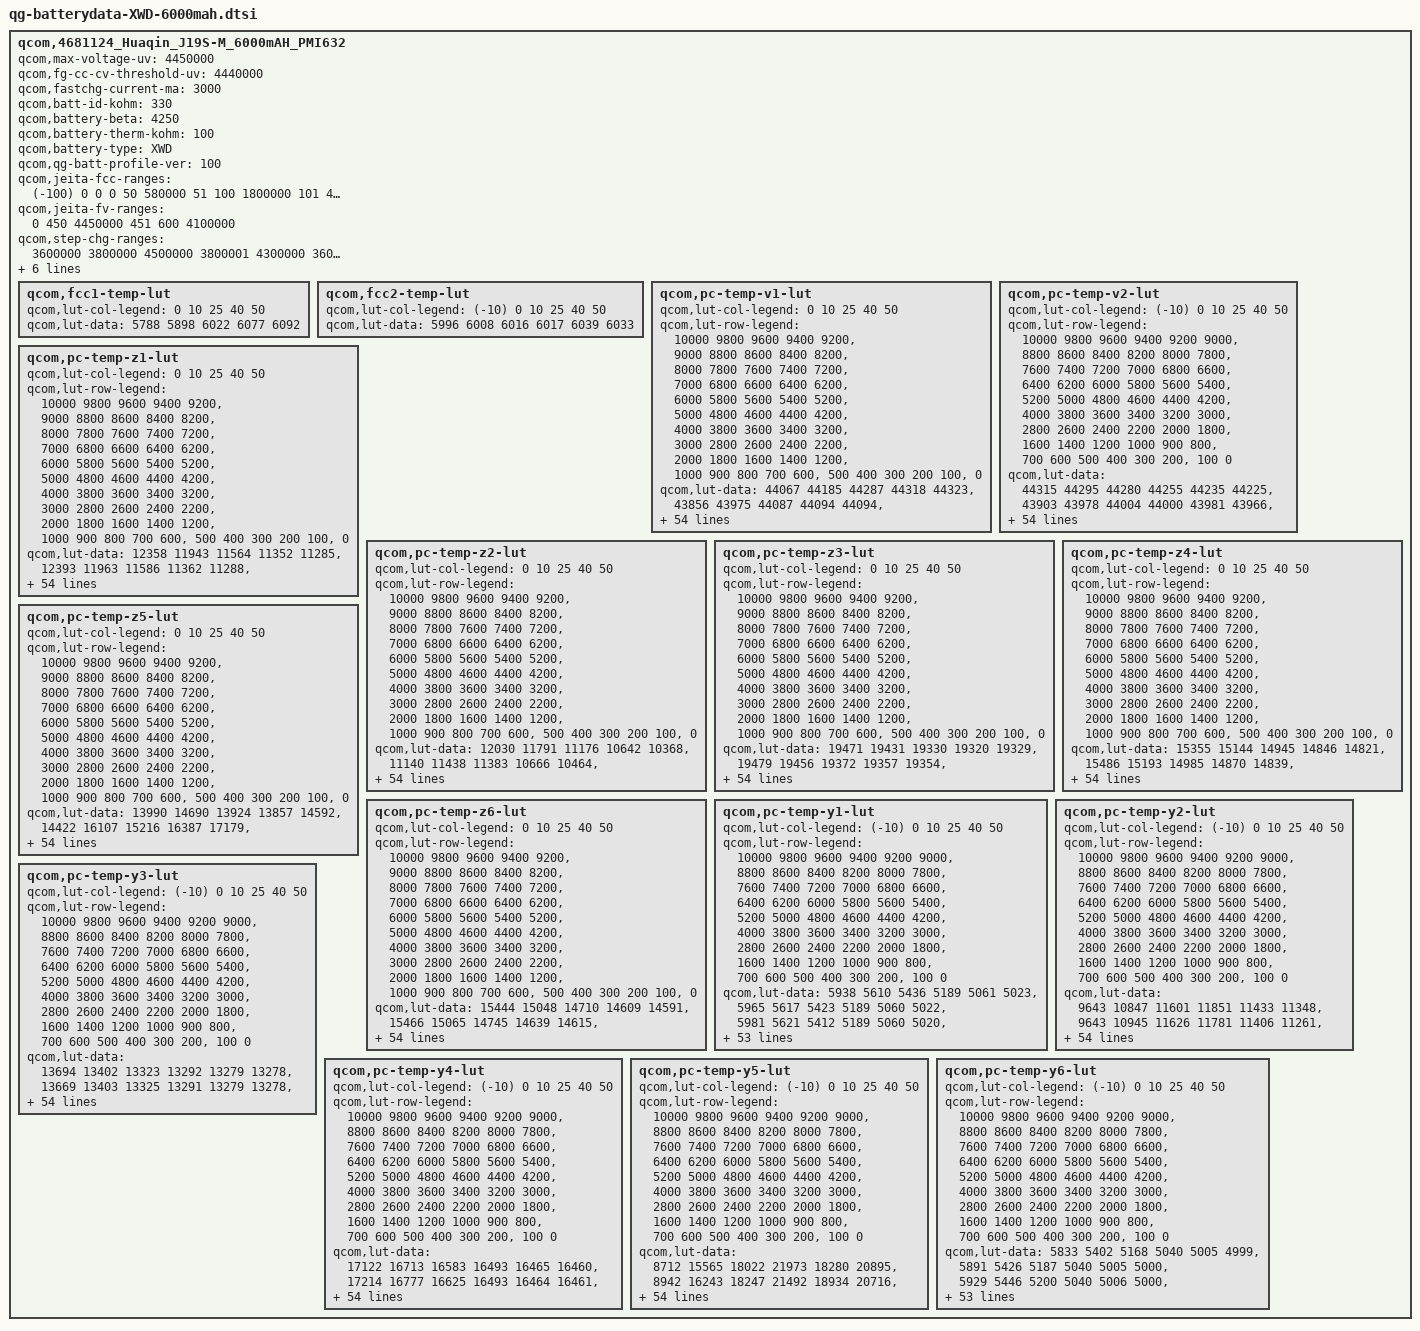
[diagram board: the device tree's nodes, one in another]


qcom,4681124_Huaqin_J19S-M_6000mAH_PMI632 {
    /* 4681124_Huaqin_J19S-M_6000mAH_PMI632_averaged_MasterSlave_Aug12th2020 */
    qcom,max-voltage-uv = <4450000>;
    qcom,fg-cc-cv-threshold-uv = <4440000>;
    qcom,fastchg-current-ma = <3000>;
    qcom,batt-id-kohm = <330>;
    qcom,battery-beta = <4250>;
    qcom,battery-therm-kohm = <100>;
    qcom,battery-type = "XWD";
    qcom,qg-batt-profile-ver = <100>;

	qcom,jeita-fcc-ranges = <(-100) 0 0
				0  50    580000
				51  100  1800000
				101 450  3000000
				451 600  3000000>;
	qcom,jeita-fv-ranges = <0   450   4450000
				451 600  4100000>;
	qcom,step-chg-ranges = <3600000  3800000  4500000
				3800001  4300000  3600000
				4300001  4350000  2500000>;
	qcom,ocv-based-step-chg;

	/* COOL = 5 DegC, WARM = 45 DegC */
	qcom,jeita-soft-thresholds = <0x439d 0x20b8>;
	/* COLD = 0 DegC, HOT = 60 DegC */
	qcom,jeita-hard-thresholds = <0x58cd 0x14f3>;
	/* COOL hys = 12 DegC, WARM hys = 40 DegC */
	qcom,jeita-soft-hys-thresholds = <0x4777 0x25e3>;
	qcom,jeita-soft-fcc-ua = <2500000 2500000>;
	qcom,jeita-soft-fv-uv = <4250000 4250000>;

	qcom,fcc1-temp-lut {
		qcom,lut-col-legend = <0 10 25 40 50>;
		qcom,lut-data = <5788 5898 6022 6077 6092>;
	};

	qcom,fcc2-temp-lut {
		qcom,lut-col-legend = <(-10) 0 10 25 40 50>;
		qcom,lut-data = <5996 6008 6016 6017 6039 6033>;
	};

	qcom,pc-temp-v1-lut {
		qcom,lut-col-legend = <0 10 25 40 50>;
		qcom,lut-row-legend = <10000 9800 9600 9400 9200>,
			<9000 8800 8600 8400 8200>,
			<8000 7800 7600 7400 7200>,
			<7000 6800 6600 6400 6200>,
			<6000 5800 5600 5400 5200>,
			<5000 4800 4600 4400 4200>,
			<4000 3800 3600 3400 3200>,
			<3000 2800 2600 2400 2200>,
			<2000 1800 1600 1400 1200>,
			<1000 900 800 700 600>,
			<500 400 300 200 100>,
			<0>;
		qcom,lut-data = <44067 44185 44287 44318 44323>,
			<43856 43975 44087 44094 44094>,
			<43631 43760 43881 43888 43886>,
			<43399 43542 43671 43683 43682>,
			<43164 43318 43454 43467 43469>,
			<42922 43083 43228 43245 43251>,
			<42680 42840 42989 43015 43024>,
			<42438 42598 42740 42775 42786>,
			<42198 42354 42493 42531 42542>,
			<41963 42112 42249 42289 42299>,
			<41735 41876 42008 42046 42055>,
			<41513 41643 41770 41806 41815>,
			<41294 41418 41536 41568 41578>,
			<41081 41201 41308 41336 41345>,
			<40872 40989 41086 41111 41119>,
			<40669 40780 40871 40893 40900>,
			<40472 40575 40663 40683 40689>,
			<40282 40381 40462 40479 40485>,
			<40098 40211 40273 40285 40291>,
			<39922 40046 40101 40110 40118>,
			<39761 39857 39919 39935 39946>,
			<39600 39636 39683 39713 39727>,
			<39403 39411 39419 39441 39447>,
			<39150 39178 39206 39214 39214>,
			<38934 38957 39032 39048 39056>,
			<38800 38822 38888 38910 38926>,
			<38698 38741 38777 38792 38801>,
			<38624 38672 38685 38690 38684>,
			<38571 38599 38597 38594 38578>,
			<38526 38528 38512 38496 38482>,
			<38478 38462 38434 38405 38396>,
			<38430 38398 38361 38324 38318>,
			<38385 38340 38292 38251 38246>,
			<38341 38289 38229 38183 38175>,
			<38299 38245 38174 38121 38105>,
			<38262 38203 38123 38061 38035>,
			<38230 38168 38076 38003 37967>,
			<38189 38129 38032 37945 37901>,
			<38122 38066 37968 37871 37818>,
			<38028 37973 37874 37768 37707>,
			<37920 37864 37764 37651 37584>,
			<37785 37730 37644 37532 37459>,
			<37630 37578 37505 37402 37325>,
			<37443 37402 37335 37235 37154>,
			<37332 37248 37187 37101 37030>,
			<37235 37152 37092 37023 36967>,
			<37200 37123 37067 36999 36938>,
			<37166 37103 37051 36979 36920>,
			<37134 37078 37026 36956 36892>,
			<37057 37015 36955 36855 36778>,
			<36766 36742 36657 36510 36418>,
			<36277 36276 36191 36032 35940>,
			<35652 35672 35587 35415 35321>,
			<34795 34843 34762 34565 34470>,
			<33394 33530 33479 33219 33117>,
			<30000 30000 30000 30000 30000>;
	};

	qcom,pc-temp-v2-lut {
		qcom,lut-col-legend = <(-10) 0 10 25 40 50>;
		qcom,lut-row-legend = <10000 9800 9600 9400 9200 9000>,
			<8800 8600 8400 8200 8000 7800>,
			<7600 7400 7200 7000 6800 6600>,
			<6400 6200 6000 5800 5600 5400>,
			<5200 5000 4800 4600 4400 4200>,
			<4000 3800 3600 3400 3200 3000>,
			<2800 2600 2400 2200 2000 1800>,
			<1600 1400 1200 1000 900 800>,
			<700 600 500 400 300 200>,
			<100 0>;
		qcom,lut-data = <44315 44295 44280 44255 44235 44225>,
			<43903 43978 44004 44000 43981 43966>,
			<43546 43688 43744 43755 43737 43719>,
			<43260 43428 43504 43522 43506 43487>,
			<43033 43200 43285 43302 43288 43270>,
			<42803 42970 43061 43078 43066 43049>,
			<42542 42723 42819 42840 42829 42814>,
			<42266 42470 42569 42596 42587 42573>,
			<41964 42217 42322 42352 42344 42331>,
			<41610 41964 42076 42108 42100 42087>,
			<41359 41706 41833 41867 41858 41846>,
			<41262 41418 41594 41628 41619 41608>,
			<41189 41141 41359 41392 41385 41375>,
			<41022 40954 41132 41164 41155 41145>,
			<40657 40832 40911 40943 40930 40921>,
			<40293 40687 40698 40728 40713 40704>,
			<40031 40454 40491 40520 40505 40495>,
			<39794 40175 40288 40318 40305 40293>,
			<39554 39926 40090 40126 40117 40107>,
			<39315 39693 39896 39947 39940 39932>,
			<39079 39460 39686 39749 39745 39741>,
			<38819 39212 39429 39499 39502 39503>,
			<38577 38970 39165 39238 39253 39257>,
			<38434 38762 38955 39026 39044 39050>,
			<38341 38579 38778 38846 38859 38865>,
			<38268 38418 38623 38693 38704 38709>,
			<38206 38267 38488 38566 38577 38581>,
			<38151 38138 38368 38455 38466 38469>,
			<38097 38062 38255 38353 38365 38365>,
			<38046 38011 38149 38258 38272 38269>,
			<37994 37966 38056 38170 38187 38181>,
			<37941 37923 37971 38086 38111 38105>,
			<37887 37881 37900 38008 38037 38031>,
			<37829 37837 37851 37936 37962 37952>,
			<37767 37792 37818 37869 37888 37869>,
			<37702 37743 37781 37801 37803 37776>,
			<37636 37686 37739 37730 37703 37667>,
			<37565 37622 37690 37656 37599 37554>,
			<37488 37546 37624 37577 37507 37457>,
			<37404 37457 37537 37494 37420 37368>,
			<37312 37353 37434 37402 37325 37272>,
			<37199 37220 37303 37296 37219 37167>,
			<37082 37084 37157 37174 37098 37047>,
			<36981 36970 37004 37024 36955 36901>,
			<36892 36857 36886 36916 36866 36815>,
			<36812 36745 36798 36868 36833 36785>,
			<36772 36681 36756 36853 36822 36774>,
			<36731 36618 36712 36834 36805 36755>,
			<36676 36554 36653 36797 36760 36704>,
			<36570 36443 36529 36685 36565 36497>,
			<36358 36236 36262 36351 36145 36065>,
			<35936 35810 35792 35826 35584 35503>,
			<35294 35163 35120 35153 34844 34762>,
			<34387 34232 34220 34224 33804 33735>,
			<32941 32628 32790 32646 32013 32000>,
			<29059 27445 28705 28453 27208 27221>;
	};

	qcom,pc-temp-z1-lut {
		qcom,lut-col-legend = <0 10 25 40 50>;
		qcom,lut-row-legend = <10000 9800 9600 9400 9200>,
			<9000 8800 8600 8400 8200>,
			<8000 7800 7600 7400 7200>,
			<7000 6800 6600 6400 6200>,
			<6000 5800 5600 5400 5200>,
			<5000 4800 4600 4400 4200>,
			<4000 3800 3600 3400 3200>,
			<3000 2800 2600 2400 2200>,
			<2000 1800 1600 1400 1200>,
			<1000 900 800 700 600>,
			<500 400 300 200 100>,
			<0>;
		qcom,lut-data = <12358 11943 11564 11352 11285>,
			<12393 11963 11586 11362 11288>,
			<12406 11972 11590 11366 11298>,
			<12414 11975 11590 11369 11305>,
			<12409 11976 11581 11367 11306>,
			<12389 11975 11571 11361 11306>,
			<12372 11971 11566 11357 11305>,
			<12366 11965 11560 11356 11303>,
			<12362 11951 11555 11354 11302>,
			<12358 11937 11548 11353 11304>,
			<12354 11929 11543 11352 11308>,
			<12349 11921 11542 11352 11310>,
			<12345 11914 11541 11353 11311>,
			<12340 11909 11540 11353 11312>,
			<12334 11906 11540 11353 11313>,
			<12323 11905 11540 11353 11314>,
			<12311 11907 11541 11353 11315>,
			<12304 11907 11541 11354 11316>,
			<12300 11906 11542 11355 11316>,
			<12298 11906 11546 11357 11318>,
			<12299 11907 11549 11360 11321>,
			<12301 11909 11548 11361 11323>,
			<12301 11911 11548 11361 11324>,
			<12296 11911 11548 11362 11326>,
			<12294 11910 11552 11364 11328>,
			<12301 11912 11557 11367 11330>,
			<12314 11918 11561 11370 11332>,
			<12319 11923 11565 11373 11334>,
			<12317 11924 11568 11376 11337>,
			<12313 11924 11571 11379 11340>,
			<12314 11926 11575 11383 11344>,
			<12317 11932 11578 11386 11348>,
			<12317 11938 11582 11390 11351>,
			<12313 11938 11585 11394 11355>,
			<12308 11936 11590 11398 11359>,
			<12311 11936 11594 11403 11364>,
			<12331 11939 11598 11407 11368>,
			<12348 11944 11601 11411 11371>,
			<12354 11950 11606 11415 11374>,
			<12358 11958 11614 11419 11378>,
			<12366 11966 11621 11423 11381>,
			<12387 11973 11625 11427 11384>,
			<12395 11981 11628 11431 11388>,
			<12391 11994 11637 11434 11389>,
			<12405 11992 11651 11439 11393>,
			<12392 12003 11649 11447 11396>,
			<12420 11997 11651 11445 11395>,
			<12544 12003 11652 11446 11397>,
			<12388 12002 11657 11448 11400>,
			<12421 11996 11661 11452 11404>,
			<12433 12016 11675 11461 11407>,
			<12422 12006 11681 11465 11411>,
			<12414 12024 11692 11473 11421>,
			<12428 12040 11698 11483 11432>,
			<12428 12040 11698 11483 11432>,
			<12428 12040 11698 11483 11432>;
	};

	qcom,pc-temp-z2-lut {
		qcom,lut-col-legend = <0 10 25 40 50>;
		qcom,lut-row-legend = <10000 9800 9600 9400 9200>,
			<9000 8800 8600 8400 8200>,
			<8000 7800 7600 7400 7200>,
			<7000 6800 6600 6400 6200>,
			<6000 5800 5600 5400 5200>,
			<5000 4800 4600 4400 4200>,
			<4000 3800 3600 3400 3200>,
			<3000 2800 2600 2400 2200>,
			<2000 1800 1600 1400 1200>,
			<1000 900 800 700 600>,
			<500 400 300 200 100>,
			<0>;
		qcom,lut-data = <12030 11791 11176 10642 10368>,
			<11140 11438 11383 10666 10464>,
			<11086 11259 11841 10733 10549>,
			<11057 11203 12015 10755 10614>,
			<11013 11154 11842 10749 10613>,
			<10961 11102 11570 10731 10561>,
			<10919 11046 11287 10708 10542>,
			<10888 11001 10965 10670 10533>,
			<10862 10963 10814 10629 10523>,
			<10847 10932 10767 10584 10519>,
			<10835 10914 10742 10543 10513>,
			<10829 10900 10739 10537 10512>,
			<10833 10895 10749 10551 10516>,
			<10840 10904 10755 10567 10520>,
			<10846 10921 10755 10583 10530>,
			<10854 10942 10757 10599 10545>,
			<10867 10970 10780 10606 10549>,
			<10887 11000 10826 10603 10557>,
			<10916 11110 10861 10604 10554>,
			<10943 11282 10884 10627 10500>,
			<10970 11313 10911 10670 10432>,
			<10990 11177 10980 10764 10488>,
			<10992 11055 11076 10965 10815>,
			<10983 11039 11093 11058 11004>,
			<10976 11031 11008 10882 10838>,
			<10982 11032 10937 10669 10616>,
			<10997 11054 10957 10675 10702>,
			<11010 11080 11007 10775 11138>,
			<11020 11099 11032 10858 11346>,
			<11030 11116 11047 10917 11148>,
			<11044 11124 11052 10954 10864>,
			<11063 11132 11048 10920 10704>,
			<11081 11139 11041 10814 10584>,
			<11094 11141 11031 10746 10499>,
			<11107 11140 11010 10708 10431>,
			<11120 11143 10997 10687 10391>,
			<11133 11156 11011 10705 10420>,
			<11151 11176 11048 10762 10517>,
			<11185 11199 11096 10838 10617>,
			<11234 11231 11180 10972 10732>,
			<11274 11264 11238 11066 10823>,
			<11303 11292 11246 11051 10863>,
			<11361 11330 11253 11025 10888>,
			<11510 11389 11268 11044 10939>,
			<10869 11756 11368 11024 10920>,
			<10531 11936 11441 10943 10669>,
			<10567 11913 11414 10817 10691>,
			<10489 11962 11374 10815 10686>,
			<10896 12014 11397 10965 10738>,
			<10801 12087 11502 10960 10772>,
			<10529 12204 11553 10832 10590>,
			<10510 12209 11303 10605 10408>,
			<10064 11914 11275 10484 10330>,
			<9893 11427 11180 10434 10282>,
			<9893 11427 11180 10434 10282>,
			<9893 11427 11180 10434 10282>;
	};

	qcom,pc-temp-z3-lut {
		qcom,lut-col-legend = <0 10 25 40 50>;
		qcom,lut-row-legend = <10000 9800 9600 9400 9200>,
			<9000 8800 8600 8400 8200>,
			<8000 7800 7600 7400 7200>,
			<7000 6800 6600 6400 6200>,
			<6000 5800 5600 5400 5200>,
			<5000 4800 4600 4400 4200>,
			<4000 3800 3600 3400 3200>,
			<3000 2800 2600 2400 2200>,
			<2000 1800 1600 1400 1200>,
			<1000 900 800 700 600>,
			<500 400 300 200 100>,
			<0>;
		qcom,lut-data = <19471 19431 19330 19320 19329>,
			<19479 19456 19372 19357 19354>,
			<19532 19471 19391 19370 19368>,
			<19582 19489 19403 19384 19378>,
			<19600 19507 19422 19394 19385>,
			<19611 19517 19438 19403 19390>,
			<19618 19523 19442 19408 19394>,
			<19627 19525 19443 19410 19397>,
			<19633 19525 19444 19411 19400>,
			<19634 19524 19443 19411 19401>,
			<19626 19523 19440 19409 19402>,
			<19619 19520 19437 19408 19401>,
			<19616 19515 19432 19405 19398>,
			<19615 19507 19426 19402 19393>,
			<19616 19499 19417 19398 19389>,
			<19618 19496 19410 19392 19385>,
			<19619 19495 19408 19388 19380>,
			<19615 19494 19406 19384 19376>,
			<19604 19492 19404 19380 19372>,
			<19599 19491 19401 19375 19364>,
			<19599 19494 19399 19370 19357>,
			<19600 19502 19406 19371 19357>,
			<19604 19506 19419 19379 19365>,
			<19618 19504 19422 19382 19369>,
			<19629 19500 19409 19369 19358>,
			<19628 19494 19396 19353 19342>,
			<19623 19486 19391 19352 19351>,
			<19617 19481 19388 19352 19390>,
			<19609 19482 19388 19354 19409>,
			<19602 19486 19395 19374 19406>,
			<19596 19490 19403 19395 19401>,
			<19592 19495 19412 19396 19395>,
			<19590 19499 19420 19394 19387>,
			<19588 19498 19422 19392 19378>,
			<19586 19496 19419 19385 19369>,
			<19584 19494 19415 19376 19360>,
			<19580 19490 19409 19368 19354>,
			<19576 19485 19401 19361 19348>,
			<19571 19480 19399 19360 19346>,
			<19563 19475 19398 19361 19346>,
			<19555 19469 19397 19362 19345>,
			<19546 19466 19394 19362 19348>,
			<19534 19461 19391 19361 19355>,
			<19516 19450 19386 19365 19364>,
			<19313 19415 19374 19362 19362>,
			<19261 19396 19364 19345 19339>,
			<19261 19397 19361 19336 19334>,
			<19262 19386 19352 19335 19325>,
			<19260 19378 19352 19324 19317>,
			<19260 19374 19342 19322 19324>,
			<19261 19333 19348 19353 19348>,
			<19261 19300 19362 19358 19352>,
			<19263 19290 19359 19356 19351>,
			<19265 19284 19355 19359 19354>,
			<19265 19284 19355 19359 19354>,
			<19265 19284 19355 19359 19354>;
	};

	qcom,pc-temp-z4-lut {
		qcom,lut-col-legend = <0 10 25 40 50>;
		qcom,lut-row-legend = <10000 9800 9600 9400 9200>,
			<9000 8800 8600 8400 8200>,
			<8000 7800 7600 7400 7200>,
			<7000 6800 6600 6400 6200>,
			<6000 5800 5600 5400 5200>,
			<5000 4800 4600 4400 4200>,
			<4000 3800 3600 3400 3200>,
			<3000 2800 2600 2400 2200>,
			<2000 1800 1600 1400 1200>,
			<1000 900 800 700 600>,
			<500 400 300 200 100>,
			<0>;
		qcom,lut-data = <15355 15144 14945 14846 14821>,
			<15486 15193 14985 14870 14839>,
			<15412 15196 14957 14857 14831>,
			<15296 15130 14925 14839 14817>,
			<15205 15044 14882 14819 14802>,
			<15123 14982 14841 14796 14785>,
			<15052 14931 14819 14777 14769>,
			<14993 14889 14803 14760 14754>,
			<14942 14855 14786 14745 14740>,
			<14905 14825 14767 14731 14726>,
			<14877 14801 14750 14719 14712>,
			<14854 14779 14734 14707 14702>,
			<14833 14763 14719 14697 14695>,
			<14811 14750 14712 14689 14690>,
			<14793 14739 14709 14685 14687>,
			<14776 14730 14707 14681 14684>,
			<14763 14722 14702 14678 14681>,
			<14758 14717 14695 14674 14679>,
			<14756 14707 14689 14670 14676>,
			<14753 14694 14684 14665 14670>,
			<14742 14693 14681 14661 14665>,
			<14730 14710 14695 14671 14673>,
			<14735 14735 14732 14715 14718>,
			<14776 14777 14764 14752 14756>,
			<14810 14826 14797 14778 14774>,
			<14816 14836 14816 14795 14786>,
			<14819 14828 14813 14794 14773>,
			<14819 14816 14804 14782 14720>,
			<14809 14802 14793 14766 14688>,
			<14794 14785 14775 14734 14681>,
			<14782 14770 14756 14702 14676>,
			<14771 14756 14736 14688 14672>,
			<14762 14745 14718 14680 14667>,
			<14755 14739 14710 14677 14666>,
			<14749 14736 14706 14677 14666>,
			<14743 14733 14704 14677 14666>,
			<14737 14729 14704 14677 14666>,
			<14732 14727 14704 14676 14665>,
			<14730 14726 14704 14677 14666>,
			<14728 14726 14708 14686 14679>,
			<14725 14726 14711 14693 14690>,
			<14718 14718 14707 14692 14685>,
			<14711 14708 14701 14688 14678>,
			<14704 14702 14698 14686 14678>,
			<14823 14680 14683 14676 14669>,
			<14853 14665 14664 14664 14660>,
			<14846 14657 14659 14664 14657>,
			<14840 14657 14652 14651 14650>,
			<14832 14658 14638 14640 14637>,
			<14835 14659 14645 14641 14627>,
			<14842 14717 14664 14648 14652>,
			<14849 14760 14657 14653 14659>,
			<14855 14774 14661 14661 14665>,
			<14862 14782 14667 14660 14665>,
			<14862 14782 14667 14660 14665>,
			<14862 14782 14667 14660 14665>;
	};

	qcom,pc-temp-z5-lut {
		qcom,lut-col-legend = <0 10 25 40 50>;
		qcom,lut-row-legend = <10000 9800 9600 9400 9200>,
			<9000 8800 8600 8400 8200>,
			<8000 7800 7600 7400 7200>,
			<7000 6800 6600 6400 6200>,
			<6000 5800 5600 5400 5200>,
			<5000 4800 4600 4400 4200>,
			<4000 3800 3600 3400 3200>,
			<3000 2800 2600 2400 2200>,
			<2000 1800 1600 1400 1200>,
			<1000 900 800 700 600>,
			<500 400 300 200 100>,
			<0>;
		qcom,lut-data = <13990 14690 13924 13857 14592>,
			<14422 16107 15216 16387 17179>,
			<15551 17139 16531 17795 19223>,
			<16761 17977 17201 19321 21019>,
			<17498 18783 18061 20579 22138>,
			<18028 19558 19149 21795 22992>,
			<18647 20279 20072 22766 23999>,
			<19675 21063 20970 23529 25269>,
			<20833 21982 21520 24259 26700>,
			<21503 23007 22138 25003 28400>,
			<21955 24145 22747 25801 30360>,
			<22269 25374 23434 26979 32069>,
			<22805 26277 24501 28869 33662>,
			<24221 26758 24982 30275 34893>,
			<25823 27231 24627 30738 35759>,
			<28540 28723 24416 31078 36421>,
			<30833 32001 25260 31854 36646>,
			<31103 34257 26880 33244 37495>,
			<31099 34267 28084 34290 38079>,
			<31182 34041 29304 34812 37448>,
			<33360 37194 30943 35481 36481>,
			<37980 47327 36421 37252 37021>,
			<44865 53695 45603 40924 40562>,
			<57798 51030 47033 42493 42567>,
			<65535 44955 36419 33776 33638>,
			<63701 39582 26387 22595 21680>,
			<57110 34033 23557 19906 22366>,
			<51639 30802 21856 18788 31034>,
			<46780 31026 21625 18607 36006>,
			<43492 32001 22532 22234 36986>,
			<43088 33634 24063 27294 37412>,
			<43330 37912 27312 30626 36883>,
			<43820 42655 32289 33468 35447>,
			<45938 45982 36097 34290 34148>,
			<48462 48839 39474 33978 32755>,
			<49344 49792 41228 33542 31719>,
			<49934 49698 40688 33148 31558>,
			<50407 49386 39533 32764 31492>,
			<50663 48312 38779 32778 31467>,
			<50648 45830 38213 34029 31370>,
			<50020 44117 37535 35103 31295>,
			<47073 43554 35012 32411 31173>,
			<44970 42729 31929 28407 31283>,
			<44517 39620 30180 30615 36802>,
			<20044 39374 30240 30908 37998>,
			<13252 37113 31027 25042 23762>,
			<13137 38257 30000 21924 21994>,
			<13131 32003 27496 24008 20898>,
			<13112 28356 31979 23532 22450>,
			<13090 27935 25863 22355 29178>,
			<13166 18475 22633 27726 27597>,
			<13012 14486 24594 25645 24354>,
			<12878 13677 22284 21920 21223>,
			<12650 13220 20033 20678 19500>,
			<12650 13220 20033 20678 19500>,
			<12650 13220 20033 20678 19500>;
	};

	qcom,pc-temp-z6-lut {
		qcom,lut-col-legend = <0 10 25 40 50>;
		qcom,lut-row-legend = <10000 9800 9600 9400 9200>,
			<9000 8800 8600 8400 8200>,
			<8000 7800 7600 7400 7200>,
			<7000 6800 6600 6400 6200>,
			<6000 5800 5600 5400 5200>,
			<5000 4800 4600 4400 4200>,
			<4000 3800 3600 3400 3200>,
			<3000 2800 2600 2400 2200>,
			<2000 1800 1600 1400 1200>,
			<1000 900 800 700 600>,
			<500 400 300 200 100>,
			<0>;
		qcom,lut-data = <15444 15048 14710 14609 14591>,
			<15466 15065 14745 14639 14615>,
			<15429 15064 14743 14640 14618>,
			<15367 15032 14737 14641 14619>,
			<15314 14988 14725 14638 14617>,
			<15260 14955 14713 14632 14612>,
			<15214 14926 14703 14627 14608>,
			<15176 14900 14695 14621 14604>,
			<15144 14877 14686 14614 14600>,
			<15116 14857 14676 14608 14595>,
			<15089 14839 14666 14602 14590>,
			<15067 14823 14656 14597 14585>,
			<15049 14809 14647 14591 14581>,
			<15033 14796 14640 14586 14576>,
			<15019 14785 14634 14581 14572>,
			<15008 14778 14629 14577 14569>,
			<14997 14773 14625 14573 14565>,
			<14987 14768 14621 14569 14562>,
			<14977 14763 14618 14565 14558>,
			<14970 14758 14614 14560 14551>,
			<14965 14759 14612 14555 14545>,
			<14962 14770 14622 14561 14549>,
			<14966 14784 14646 14586 14575>,
			<14994 14803 14659 14601 14590>,
			<15015 14822 14667 14604 14591>,
			<15017 14825 14670 14605 14590>,
			<15017 14819 14668 14604 14590>,
			<15017 14812 14664 14600 14588>,
			<15009 14807 14660 14595 14586>,
			<15000 14803 14656 14593 14582>,
			<14993 14799 14653 14590 14578>,
			<14987 14797 14650 14587 14573>,
			<14982 14795 14648 14583 14568>,
			<14980 14793 14645 14580 14563>,
			<14978 14792 14644 14576 14559>,
			<14977 14791 14642 14573 14555>,
			<14976 14789 14639 14570 14551>,
			<14975 14788 14636 14566 14548>,
			<14976 14788 14635 14566 14548>,
			<14979 14789 14638 14570 14552>,
			<14980 14789 14640 14574 14557>,
			<14979 14788 14639 14573 14558>,
			<14978 14786 14636 14572 14558>,
			<14976 14784 14635 14574 14562>,
			<14942 14768 14625 14569 14559>,
			<14930 14755 14615 14556 14543>,
			<14928 14753 14610 14551 14539>,
			<14926 14749 14604 14545 14532>,
			<14925 14746 14598 14535 14521>,
			<14933 14749 14598 14535 14522>,
			<14942 14757 14612 14556 14546>,
			<14950 14764 14618 14563 14554>,
			<14962 14770 14622 14567 14558>,
			<14979 14780 14627 14571 14563>,
			<14979 14780 14627 14571 14563>,
			<14979 14780 14627 14571 14563>;
	};

	qcom,pc-temp-y1-lut {
		qcom,lut-col-legend = <(-10) 0 10 25 40 50>;
		qcom,lut-row-legend = <10000 9800 9600 9400 9200 9000>,
			<8800 8600 8400 8200 8000 7800>,
			<7600 7400 7200 7000 6800 6600>,
			<6400 6200 6000 5800 5600 5400>,
			<5200 5000 4800 4600 4400 4200>,
			<4000 3800 3600 3400 3200 3000>,
			<2800 2600 2400 2200 2000 1800>,
			<1600 1400 1200 1000 900 800>,
			<700 600 500 400 300 200>,
			<100 0>;
		qcom,lut-data = <5938 5610 5436 5189 5061 5023>,
			<5965 5617 5423 5189 5060 5022>,
			<5981 5621 5412 5189 5060 5020>,
			<5989 5624 5405 5188 5059 5018>,
			<5992 5626 5401 5186 5058 5017>,
			<5993 5627 5400 5184 5057 5016>,
			<5985 5625 5403 5181 5055 5015>,
			<5973 5621 5409 5177 5053 5014>,
			<5971 5620 5409 5176 5051 5014>,
			<5974 5617 5408 5176 5049 5012>,
			<5978 5616 5405 5175 5048 5012>,
			<5986 5618 5400 5175 5048 5012>,
			<5995 5621 5395 5174 5047 5013>,
			<5996 5626 5395 5173 5047 5013>,
			<5990 5637 5399 5171 5049 5011>,
			<5988 5644 5401 5171 5049 5011>,
			<5995 5638 5402 5171 5048 5014>,
			<6007 5631 5402 5172 5046 5018>,
			<6008 5630 5403 5173 5046 5018>,
			<6000 5631 5408 5173 5048 5016>,
			<5995 5632 5412 5174 5049 5015>,
			<6001 5640 5408 5176 5051 5016>,
			<6010 5651 5403 5178 5052 5017>,
			<6011 5653 5403 5181 5053 5018>,
			<6007 5651 5407 5185 5055 5020>,
			<6004 5648 5411 5188 5057 5022>,
			<6003 5645 5413 5189 5059 5024>,
			<6002 5641 5415 5189 5061 5026>,
			<6002 5640 5416 5191 5063 5028>,
			<6009 5641 5417 5197 5066 5030>,
			<6014 5642 5418 5201 5068 5032>,
			<6013 5642 5420 5203 5070 5034>,
			<6010 5642 5423 5206 5072 5036>,
			<6008 5643 5426 5213 5076 5038>,
			<6006 5648 5428 5229 5080 5041>,
			<6006 5653 5430 5240 5082 5043>,
			<6022 5658 5431 5232 5083 5045>,
			<6049 5661 5433 5220 5084 5047>,
			<6051 5661 5436 5219 5086 5049>,
			<6034 5655 5442 5225 5087 5050>,
			<6021 5653 5445 5228 5089 5051>,
			<6033 5663 5441 5227 5091 5053>,
			<6045 5672 5439 5227 5092 5054>,
			<6024 5667 5448 5237 5095 5056>,
			<6026 5678 5447 5244 5099 5060>,
			<6039 5693 5446 5243 5100 5059>,
			<6042 5685 5455 5247 5100 5059>,
			<6054 5696 5452 5239 5098 5057>,
			<6064 5704 5448 5245 5099 5059>,
			<6098 5724 5461 5243 5100 5062>,
			<6108 5717 5465 5244 5101 5063>,
			<6132 5718 5469 5256 5105 5065>,
			<6228 5756 5480 5262 5111 5070>,
			<6253 5804 5503 5273 5119 5077>,
			<6253 5804 5503 5273 5119 5077>,
			<6253 5804 5503 5273 5119 5077>;
	};

	qcom,pc-temp-y2-lut {
		qcom,lut-col-legend = <(-10) 0 10 25 40 50>;
		qcom,lut-row-legend = <10000 9800 9600 9400 9200 9000>,
			<8800 8600 8400 8200 8000 7800>,
			<7600 7400 7200 7000 6800 6600>,
			<6400 6200 6000 5800 5600 5400>,
			<5200 5000 4800 4600 4400 4200>,
			<4000 3800 3600 3400 3200 3000>,
			<2800 2600 2400 2200 2000 1800>,
			<1600 1400 1200 1000 900 800>,
			<700 600 500 400 300 200>,
			<100 0>;
		qcom,lut-data = <9643 10847 11601 11851 11433 11348>,
			<9643 10945 11626 11781 11406 11261>,
			<9643 11062 11637 11698 11339 11176>,
			<9963 11174 11637 11614 11256 11101>,
			<10409 11258 11630 11545 11182 11046>,
			<10620 11291 11619 11504 11141 11018>,
			<10656 11279 11578 11487 11113 11023>,
			<10675 11253 11518 11475 11087 11035>,
			<10580 11226 11487 11457 11080 11012>,
			<10060 11192 11467 11430 11065 10927>,
			<9718 11174 11459 11414 11059 10874>,
			<9717 11280 11461 11426 11071 10880>,
			<9717 11438 11468 11446 11085 10894>,
			<9714 11457 11486 11447 11067 10896>,
			<9707 11402 11541 11444 10985 10892>,
			<9699 11368 11608 11453 10942 10890>,
			<9691 11462 11687 11493 11020 10904>,
			<9684 11613 11775 11559 11150 10932>,
			<9680 11673 11852 11652 11247 10986>,
			<9677 11701 11930 11797 11337 11110>,
			<9675 11714 11964 11870 11398 11219>,
			<9674 11715 11936 11835 11453 11305>,
			<9673 11712 11896 11788 11494 11364>,
			<9672 11697 11899 11791 11481 11353>,
			<9671 11634 11940 11838 11434 11290>,
			<9669 11521 11984 11890 11414 11259>,
			<9668 10848 12033 11934 11449 11277>,
			<9667 9966 12074 11978 11514 11313>,
			<9667 9774 12075 12023 11602 11380>,
			<9666 9742 12056 12080 11734 11506>,
			<9666 9724 12045 12125 11822 11600>,
			<9665 9712 12051 12156 11863 11659>,
			<9665 9704 12060 12179 11896 11697>,
			<9665 9695 12052 12185 11936 11705>,
			<9664 9687 12000 12173 11978 11697>,
			<9664 9681 11929 12159 11986 11684>,
			<9664 9676 11822 12136 11869 11660>,
			<9664 9672 11690 12107 11736 11624>,
			<9664 9670 11577 12087 11706 11578>,
			<9664 9668 11480 12066 11698 11519>,
			<9664 9666 11343 12037 11696 11470>,
			<9663 9665 10936 11996 11639 11434>,
			<9663 9664 10431 11948 11596 11393>,
			<9663 9663 9858 11882 11482 11299>,
			<9662 9662 9741 11727 11365 11204>,
			<9661 9662 9749 11654 11276 11052>,
			<9661 9661 9723 11599 11289 11119>,
			<9660 9661 9715 11581 11332 11150>,
			<9660 9660 9707 11557 11337 11147>,
			<9658 9660 9700 11569 11304 11096>,
			<9656 9659 9690 11514 11250 11031>,
			<9653 9658 9678 11430 11143 10964>,
			<9652 9656 9667 11267 11005 10834>,
			<9650 9653 9661 11111 10815 10653>,
			<9650 9653 9661 11111 10815 10653>,
			<9650 9653 9661 11111 10815 10653>;
	};

	qcom,pc-temp-y3-lut {
		qcom,lut-col-legend = <(-10) 0 10 25 40 50>;
		qcom,lut-row-legend = <10000 9800 9600 9400 9200 9000>,
			<8800 8600 8400 8200 8000 7800>,
			<7600 7400 7200 7000 6800 6600>,
			<6400 6200 6000 5800 5600 5400>,
			<5200 5000 4800 4600 4400 4200>,
			<4000 3800 3600 3400 3200 3000>,
			<2800 2600 2400 2200 2000 1800>,
			<1600 1400 1200 1000 900 800>,
			<700 600 500 400 300 200>,
			<100 0>;
		qcom,lut-data = <13694 13402 13323 13292 13279 13278>,
			<13669 13403 13325 13291 13279 13278>,
			<13643 13404 13328 13291 13280 13279>,
			<13619 13406 13332 13291 13281 13279>,
			<13598 13407 13335 13291 13282 13280>,
			<13583 13408 13337 13291 13282 13281>,
			<13574 13410 13337 13291 13283 13281>,
			<13567 13411 13337 13291 13283 13282>,
			<13555 13411 13338 13292 13284 13282>,
			<13534 13409 13340 13293 13285 13282>,
			<13523 13406 13341 13294 13285 13283>,
			<13526 13397 13342 13293 13286 13284>,
			<13532 13386 13343 13292 13286 13285>,
			<13534 13383 13342 13293 13286 13285>,
			<13533 13383 13340 13298 13286 13285>,
			<13533 13383 13337 13301 13286 13284>,
			<13521 13381 13335 13301 13287 13285>,
			<13504 13378 13333 13301 13290 13286>,
			<13499 13374 13332 13301 13292 13287>,
			<13499 13366 13330 13300 13294 13290>,
			<13498 13358 13329 13300 13295 13292>,
			<13487 13350 13324 13297 13291 13288>,
			<13472 13342 13317 13293 13286 13284>,
			<13472 13337 13314 13291 13283 13281>,
			<13492 13332 13311 13288 13280 13279>,
			<13517 13326 13309 13287 13279 13278>,
			<13545 13304 13307 13286 13277 13278>,
			<13577 13277 13306 13286 13277 13278>,
			<13613 13276 13304 13286 13277 13277>,
			<13654 13290 13302 13287 13278 13276>,
			<13697 13306 13301 13287 13279 13276>,
			<13742 13320 13300 13286 13279 13276>,
			<13788 13337 13300 13284 13279 13277>,
			<13835 13357 13301 13284 13279 13278>,
			<13881 13383 13304 13284 13280 13279>,
			<13926 13415 13307 13284 13281 13279>,
			<13968 13457 13309 13284 13280 13278>,
			<14008 13507 13311 13284 13279 13278>,
			<14045 13564 13313 13285 13280 13278>,
			<14080 13631 13315 13285 13281 13280>,
			<14112 13700 13318 13286 13282 13280>,
			<14137 13768 13322 13288 13282 13281>,
			<14164 13841 13327 13289 13281 13280>,
			<14206 13924 13339 13287 13278 13277>,
			<14267 14008 13361 13290 13281 13280>,
			<14283 13999 13360 13292 13286 13285>,
			<14345 14063 13377 13296 13289 13287>,
			<14433 14123 13403 13301 13292 13289>,
			<14552 14190 13431 13305 13293 13289>,
			<14719 14248 13456 13305 13289 13286>,
			<15034 14345 13484 13302 13287 13285>,
			<15985 14515 13538 13303 13289 13286>,
			<18490 14976 13694 13310 13294 13290>,
			<25239 16662 14071 13320 13300 13299>,
			<25239 16662 14071 13320 13300 13299>,
			<25239 16662 14071 13320 13300 13299>;
	};

	qcom,pc-temp-y4-lut {
		qcom,lut-col-legend = <(-10) 0 10 25 40 50>;
		qcom,lut-row-legend = <10000 9800 9600 9400 9200 9000>,
			<8800 8600 8400 8200 8000 7800>,
			<7600 7400 7200 7000 6800 6600>,
			<6400 6200 6000 5800 5600 5400>,
			<5200 5000 4800 4600 4400 4200>,
			<4000 3800 3600 3400 3200 3000>,
			<2800 2600 2400 2200 2000 1800>,
			<1600 1400 1200 1000 900 800>,
			<700 600 500 400 300 200>,
			<100 0>;
		qcom,lut-data = <17122 16713 16583 16493 16465 16460>,
			<17214 16777 16625 16493 16464 16461>,
			<17278 16862 16667 16493 16464 16461>,
			<17319 16947 16703 16495 16463 16462>,
			<17341 17012 16728 16496 16463 16462>,
			<17347 17038 16737 16497 16464 16462>,
			<17324 17031 16731 16497 16464 16462>,
			<17287 17016 16717 16497 16465 16461>,
			<17284 17002 16707 16498 16465 16461>,
			<17307 16986 16697 16500 16466 16462>,
			<17343 16975 16691 16503 16467 16463>,
			<17426 16969 16688 16508 16470 16464>,
			<17523 16964 16686 16515 16473 16465>,
			<17510 16985 16690 16519 16478 16468>,
			<17336 17089 16708 16520 16485 16472>,
			<17183 17154 16729 16523 16491 16477>,
			<17126 17106 16753 16532 16495 16481>,
			<17084 17022 16775 16549 16498 16486>,
			<17026 16969 16782 16572 16509 16495>,
			<16950 16934 16783 16607 16531 16510>,
			<16874 16894 16779 16623 16540 16517>,
			<16790 16829 16726 16593 16528 16510>,
			<16717 16756 16645 16542 16508 16497>,
			<16704 16697 16605 16512 16491 16484>,
			<16704 16640 16580 16490 16471 16466>,
			<16704 16615 16564 16481 16463 16458>,
			<16706 16619 16556 16483 16465 16459>,
			<16710 16624 16550 16486 16470 16461>,
			<16713 16626 16542 16490 16474 16464>,
			<16718 16627 16533 16495 16479 16471>,
			<16723 16629 16524 16500 16486 16478>,
			<16728 16638 16512 16506 16496 16486>,
			<16733 16652 16502 16510 16504 16493>,
			<16739 16665 16504 16511 16505 16496>,
			<16745 16681 16520 16510 16504 16497>,
			<16752 16695 16539 16509 16503 16497>,
			<16758 16708 16561 16500 16489 16486>,
			<16764 16718 16584 16488 16474 16473>,
			<16765 16723 16602 16486 16472 16473>,
			<16763 16726 16616 16485 16471 16475>,
			<16761 16728 16627 16485 16472 16478>,
			<16756 16723 16635 16493 16477 16484>,
			<16750 16720 16644 16498 16478 16484>,
			<16744 16726 16658 16495 16458 16454>,
			<16747 16744 16676 16497 16455 16450>,
			<16742 16735 16667 16498 16481 16491>,
			<16754 16764 16695 16516 16512 16527>,
			<16775 16810 16737 16542 16549 16563>,
			<16803 16863 16795 16579 16573 16580>,
			<16829 16916 16849 16593 16528 16529>,
			<16827 16943 16869 16544 16479 16479>,
			<16927 16908 16871 16531 16478 16479>,
			<17446 16897 16910 16553 16482 16480>,
			<20254 17435 17005 16588 16518 16509>,
			<20254 17435 17005 16588 16518 16509>,
			<20254 17435 17005 16588 16518 16509>;
	};

	qcom,pc-temp-y5-lut {
		qcom,lut-col-legend = <(-10) 0 10 25 40 50>;
		qcom,lut-row-legend = <10000 9800 9600 9400 9200 9000>,
			<8800 8600 8400 8200 8000 7800>,
			<7600 7400 7200 7000 6800 6600>,
			<6400 6200 6000 5800 5600 5400>,
			<5200 5000 4800 4600 4400 4200>,
			<4000 3800 3600 3400 3200 3000>,
			<2800 2600 2400 2200 2000 1800>,
			<1600 1400 1200 1000 900 800>,
			<700 600 500 400 300 200>,
			<100 0>;
		qcom,lut-data = <8712 15565 18022 21973 18280 20895>,
			<8942 16243 18247 21492 18934 20716>,
			<11758 16898 18579 20620 19125 20515>,
			<14652 17514 18928 19587 19018 20327>,
			<17058 18072 19203 18623 18780 20189>,
			<18410 18556 19314 17958 18576 20136>,
			<18965 19051 19286 17432 18174 20039>,
			<19296 19442 19239 16911 17651 19821>,
			<18815 19474 19221 16598 17432 19473>,
			<16011 19260 19213 16392 17221 18763>,
			<14180 18891 19181 16129 17016 18265>,
			<15778 17306 18947 15511 16712 18110>,
			<18448 15263 18473 14867 16279 17973>,
			<19428 15348 17733 14929 15759 17587>,
			<19833 17608 16412 15658 15084 16629>,
			<19991 19379 15715 16084 14787 15950>,
			<19363 19837 16156 15741 15123 15766>,
			<18371 20164 17128 15258 15618 15739>,
			<18357 20827 18473 15277 15873 15870>,
			<19352 22005 20660 15868 16127 16341>,
			<20015 22834 22343 16781 16493 16945>,
			<17858 23105 23272 19339 18556 18493>,
			<14301 23312 23894 22153 20798 20091>,
			<13186 23766 24056 22372 20812 20257>,
			<12848 24649 24068 21655 19976 20161>,
			<12696 25118 24032 21175 19059 19986>,
			<12704 20400 23987 20924 17782 19223>,
			<12784 13634 23952 20720 16738 18144>,
			<12869 12534 24007 20856 16759 17245>,
			<12989 12775 24242 21353 17111 16353>,
			<13125 13050 24352 21616 17360 16034>,
			<13309 13289 23536 21205 17493 16311>,
			<13515 13545 22500 20672 17684 16840>,
			<13630 13842 22175 20784 18519 17701>,
			<13699 14195 21880 21434 20382 19201>,
			<13775 14517 21496 21877 21483 20433>,
			<13917 14776 20620 22179 21858 21245>,
			<14100 15003 19591 22439 22171 21953>,
			<14271 15238 19080 22205 22765 22748>,
			<14500 15512 18728 21278 23594 23559>,
			<14625 15634 18560 20730 23816 23827>,
			<14075 15016 17999 20725 22756 23375>,
			<13406 14502 17106 20673 21555 22713>,
			<13316 14684 15200 19072 19747 20998>,
			<13245 14438 14814 18746 19074 20440>,
			<13095 14269 14656 18547 18025 17675>,
			<13135 14236 14645 18582 17810 16886>,
			<13258 14437 15088 18848 17834 16546>,
			<13495 15412 15834 18918 17736 16322>,
			<13541 15906 16074 19269 17710 16627>,
			<14041 16065 15902 20061 18400 17791>,
			<12450 14999 15041 20248 18998 16793>,
			<10590 13601 13863 20398 19975 17598>,
			<9461 11045 13303 21105 24194 24327>,
			<9461 11045 13303 21105 24194 24327>,
			<9461 11045 13303 21105 24194 24327>;
	};

	qcom,pc-temp-y6-lut {
		qcom,lut-col-legend = <(-10) 0 10 25 40 50>;
		qcom,lut-row-legend = <10000 9800 9600 9400 9200 9000>,
			<8800 8600 8400 8200 8000 7800>,
			<7600 7400 7200 7000 6800 6600>,
			<6400 6200 6000 5800 5600 5400>,
			<5200 5000 4800 4600 4400 4200>,
			<4000 3800 3600 3400 3200 3000>,
			<2800 2600 2400 2200 2000 1800>,
			<1600 1400 1200 1000 900 800>,
			<700 600 500 400 300 200>,
			<100 0>;
		qcom,lut-data = <5833 5402 5168 5040 5005 4999>,
			<5891 5426 5187 5040 5005 5000>,
			<5929 5446 5200 5040 5006 5000>,
			<5951 5460 5208 5040 5006 5001>,
			<5961 5469 5212 5040 5007 5002>,
			<5964 5472 5214 5040 5007 5002>,
			<5954 5467 5210 5040 5008 5002>,
			<5933 5459 5203 5039 5008 5003>,
			<5908 5451 5198 5040 5009 5003>,
			<5872 5443 5194 5040 5009 5004>,
			<5853 5435 5191 5041 5010 5004>,
			<5878 5423 5188 5042 5011 5005>,
			<5916 5412 5187 5044 5012 5006>,
			<5915 5417 5187 5045 5014 5007>,
			<5869 5447 5189 5048 5015 5008>,
			<5825 5466 5192 5051 5017 5009>,
			<5801 5453 5197 5055 5019 5011>,
			<5783 5429 5202 5059 5022 5013>,
			<5767 5413 5203 5065 5027 5017>,
			<5752 5401 5203 5075 5035 5023>,
			<5736 5387 5201 5079 5038 5026>,
			<5715 5367 5183 5069 5031 5022>,
			<5695 5346 5156 5051 5022 5014>,
			<5694 5332 5143 5041 5014 5008>,
			<5714 5322 5135 5034 5007 5001>,
			<5739 5315 5131 5031 5004 4999>,
			<5764 5311 5130 5031 5004 4999>,
			<5792 5308 5129 5032 5005 4999>,
			<5823 5311 5128 5034 5006 5000>,
			<5856 5333 5126 5036 5009 5002>,
			<5891 5359 5125 5039 5011 5004>,
			<5927 5387 5125 5040 5014 5006>,
			<5964 5419 5125 5041 5016 5009>,
			<6002 5454 5128 5042 5018 5011>,
			<6039 5495 5140 5042 5019 5012>,
			<6075 5540 5154 5042 5019 5012>,
			<6110 5589 5169 5040 5014 5009>,
			<6143 5643 5186 5038 5010 5005>,
			<6173 5699 5205 5038 5010 5005>,
			<6200 5758 5227 5039 5011 5007>,
			<6225 5817 5251 5040 5012 5009>,
			<6246 5874 5277 5045 5013 5011>,
			<6268 5934 5305 5048 5013 5010>,
			<6301 6003 5336 5048 5006 5000>,
			<6354 6078 5382 5053 5008 5002>,
			<6372 6073 5377 5055 5019 5017>,
			<6427 6132 5410 5064 5030 5029>,
			<6505 6195 5452 5075 5043 5041>,
			<6612 6267 5497 5087 5050 5046>,
			<6760 6334 5538 5092 5034 5029>,
			<7023 6421 5582 5076 5020 5015>,
			<7824 6550 5654 5075 5022 5015>,
			<9873 6914 5820 5091 5027 5019>,
			<15418 8363 6165 5115 5043 5037>,
			<15418 8363 6165 5115 5043 5037>,
			<15418 8363 6165 5115 5043 5037>;
	};

};
